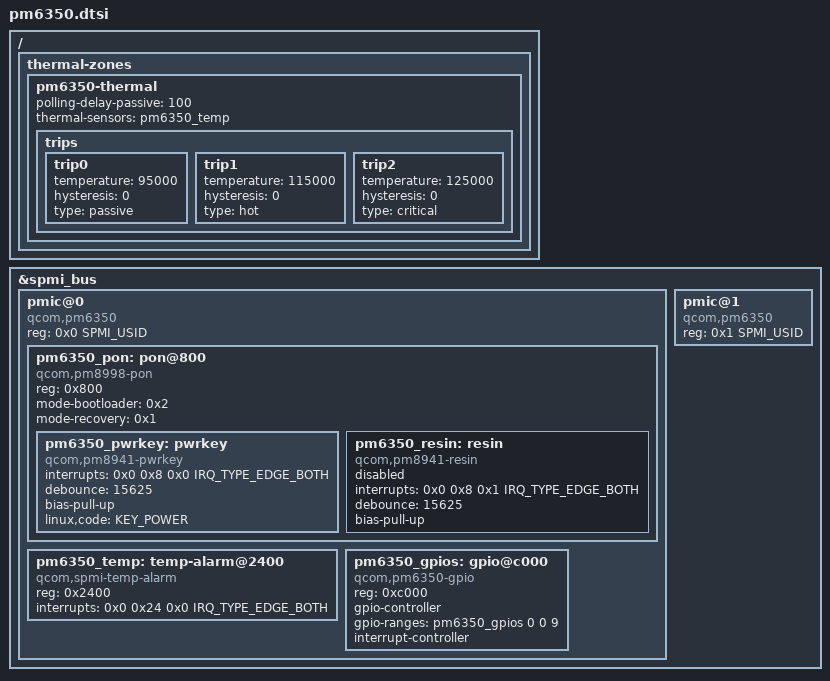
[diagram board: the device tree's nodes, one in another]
// SPDX-License-Identifier: BSD-3-Clause
/*
 * Copyright (c) 2021, Luca Weiss <luca@z3ntu.xyz>
 */

#include <dt-bindings/input/input.h>
#include <dt-bindings/spmi/spmi.h>

/ {
	thermal-zones {
		pm6350-thermal {
			polling-delay-passive = <100>;

			thermal-sensors = <&pm6350_temp>;

			trips {
				trip0 {
					temperature = <95000>;
					hysteresis = <0>;
					type = "passive";
				};

				trip1 {
					temperature = <115000>;
					hysteresis = <0>;
					type = "hot";
				};

				trip2 {
					temperature = <125000>;
					hysteresis = <0>;
					type = "critical";
				};
			};
		};
	};
};

&spmi_bus {
	pmic@0 {
		compatible = "qcom,pm6350", "qcom,spmi-pmic";
		reg = <0x0 SPMI_USID>;
		#address-cells = <1>;
		#size-cells = <0>;

		pm6350_pon: pon@800 {
			compatible = "qcom,pm8998-pon";
			reg = <0x800>;
			mode-bootloader = <0x2>;
			mode-recovery = <0x1>;

			pm6350_pwrkey: pwrkey {
				compatible = "qcom,pm8941-pwrkey";
				interrupts = <0x0 0x8 0x0 IRQ_TYPE_EDGE_BOTH>;
				debounce = <15625>;
				bias-pull-up;
				linux,code = <KEY_POWER>;
			};

			pm6350_resin: resin {
				compatible = "qcom,pm8941-resin";
				interrupts = <0x0 0x8 0x1 IRQ_TYPE_EDGE_BOTH>;
				debounce = <15625>;
				bias-pull-up;
				status = "disabled";
			};
		};

		pm6350_temp: temp-alarm@2400 {
			compatible = "qcom,spmi-temp-alarm";
			reg = <0x2400>;
			interrupts = <0x0 0x24 0x0 IRQ_TYPE_EDGE_BOTH>;
			#thermal-sensor-cells = <0>;
		};

		pm6350_gpios: gpio@c000 {
			compatible = "qcom,pm6350-gpio", "qcom,spmi-gpio";
			reg = <0xc000>;
			gpio-controller;
			gpio-ranges = <&pm6350_gpios 0 0 9>;
			#gpio-cells = <2>;
			interrupt-controller;
			#interrupt-cells = <2>;
		};
	};

	pmic@1 {
		compatible = "qcom,pm6350", "qcom,spmi-pmic";
		reg = <0x1 SPMI_USID>;
		#address-cells = <1>;
		#size-cells = <0>;
	};
};
